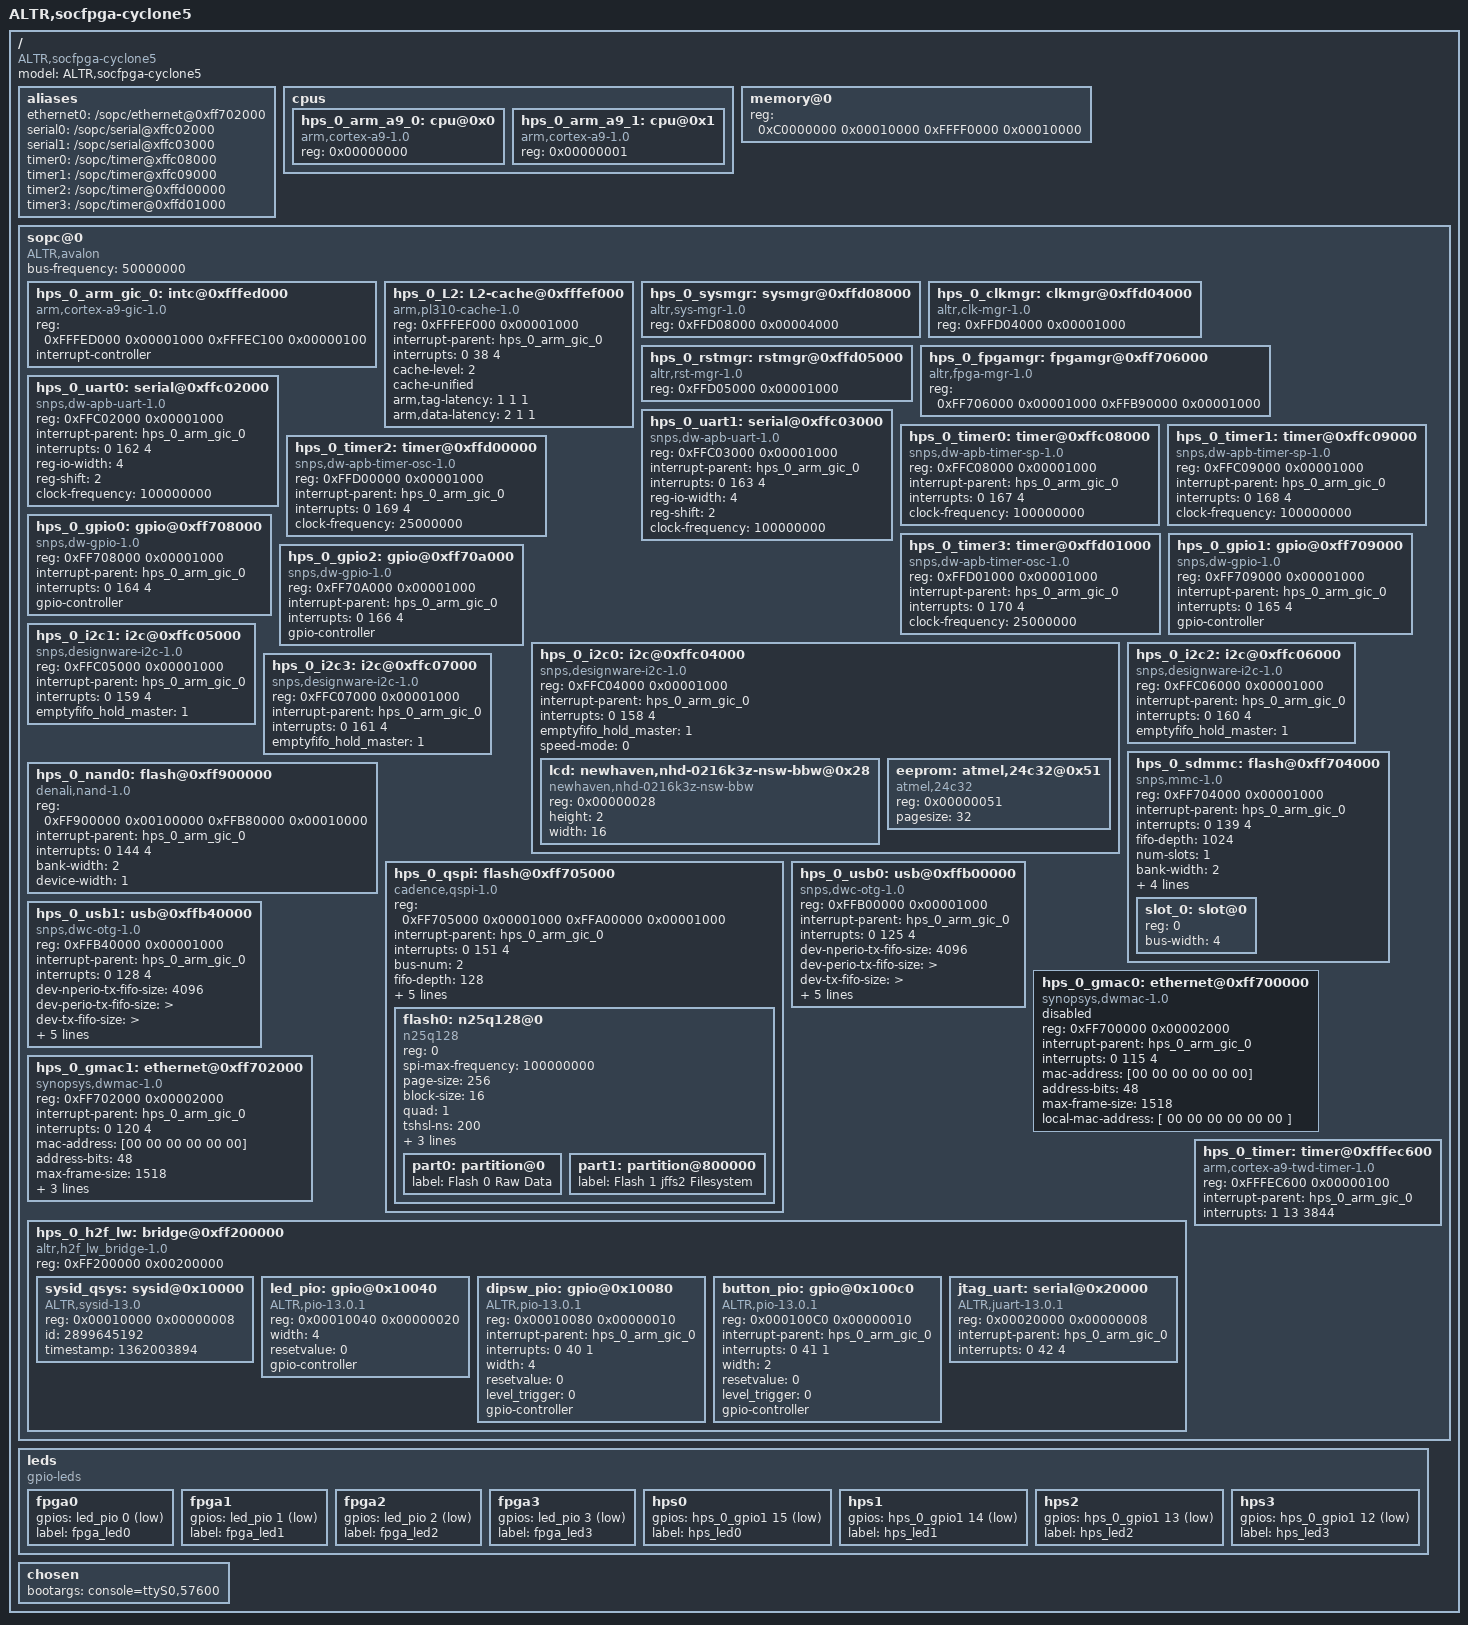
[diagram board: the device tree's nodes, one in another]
/*
 * This devicetree is generated by sopc2dts on Thu Feb 28 06:48:45 MYT 2013
 * Sopc2dts is written by Walter Goossens <waltergoossens@home.nl>
 * in cooperation with the nios2 community <Nios2-dev@sopc.et.ntust.edu.tw>
 */
/dts-v1/;

/ {
	model = "ALTR,socfpga-cyclone5";
	compatible = "ALTR,socfpga-cyclone5";
	#address-cells = < 1 >;
	#size-cells = < 1 >;

	aliases {
		ethernet0 = "/sopc/ethernet@0xff702000";
		serial0 = "/sopc/serial@xffc02000";
		serial1 = "/sopc/serial@xffc03000";
		timer0 = "/sopc/timer@xffc08000";
		timer1 = "/sopc/timer@xffc09000";
		timer2 = "/sopc/timer@0xffd00000";
		timer3 = "/sopc/timer@0xffd01000";
	}; //end aliases

	cpus {
		#address-cells = < 1 >;
		#size-cells = < 0 >;

		hps_0_arm_a9_0: cpu@0x0 {
			device_type = "cpu";
			compatible = "arm,cortex-a9-1.0", "arm,cortex-a9";
			reg = < 0x00000000 >;
		}; //end cpu@0x0 (hps_0_arm_a9_0)

		hps_0_arm_a9_1: cpu@0x1 {
			device_type = "cpu";
			compatible = "arm,cortex-a9-1.0", "arm,cortex-a9";
			reg = < 0x00000001 >;
		}; //end cpu@0x1 (hps_0_arm_a9_1)
	}; //end cpus

	memory@0 {
		device_type = "memory";
		reg = < 0xC0000000 0x00010000
			0xFFFF0000 0x00010000 >;
	}; //end memory@0

	sopc@0 {
		device_type = "soc";
		ranges;
		#address-cells = < 1 >;
		#size-cells = < 1 >;
		compatible = "ALTR,avalon", "simple-bus";
		bus-frequency = < 50000000 >;

		hps_0_arm_gic_0: intc@0xfffed000 {
			compatible = "arm,cortex-a9-gic-1.0", "arm,cortex-a9-gic";
			reg = < 0xFFFED000 0x00001000
				0xFFFEC100 0x00000100 >;
			interrupt-controller;
			#interrupt-cells = < 3 >;
		}; //end intc@0xfffed000 (hps_0_arm_gic_0)

		hps_0_L2: L2-cache@0xfffef000 {
			compatible = "arm,pl310-cache-1.0", "arm,pl310-cache";
			reg = < 0xFFFEF000 0x00001000 >;
			interrupt-parent = < &hps_0_arm_gic_0 >;
			interrupts = < 0 38 4 >;
			cache-level = < 2 >;	/* embeddedsw.dts.params.cache-level type NUMBER */
			cache-unified;	/* appended from boardinfo*/
			arm,tag-latency = <1 1 1>;
			arm,data-latency = <2 1 1>;
		}; //end L2-cache@0xfffef000 (hps_0_L2)

		hps_0_sysmgr: sysmgr@0xffd08000 {
			compatible = "altr,sys-mgr-1.0", "altr,sys-mgr";
			reg = < 0xFFD08000 0x00004000 >;
		}; //end sysmgr@0xffd08000 (hps_0_sysmgr)

		hps_0_clkmgr: clkmgr@0xffd04000 {
			compatible = "altr,clk-mgr-1.0", "altr,clk-mgr";
			reg = < 0xFFD04000 0x00001000 >;
		}; //end clkmgr@0xffd04000 (hps_0_clkmgr)

		hps_0_rstmgr: rstmgr@0xffd05000 {
			compatible = "altr,rst-mgr-1.0", "altr,rst-mgr";
			reg = < 0xFFD05000 0x00001000 >;
		}; //end rstmgr@0xffd05000 (hps_0_rstmgr)

		hps_0_fpgamgr: fpgamgr@0xff706000 {
			compatible = "altr,fpga-mgr-1.0", "altr,fpga-mgr";
			reg = < 0xFF706000 0x00001000
				0xFFB90000 0x00001000 >;
		}; //end fpgamgr@0xff706000 (hps_0_fpgamgr)

		hps_0_uart0: serial@0xffc02000 {
			compatible = "snps,dw-apb-uart-1.0", "snps,dw-apb-uart";
			reg = < 0xFFC02000 0x00001000 >;
			interrupt-parent = < &hps_0_arm_gic_0 >;
			interrupts = < 0 162 4 >;
			reg-io-width = < 4 >;	/* embeddedsw.dts.params.reg-io-width type NUMBER */
			reg-shift = < 2 >;	/* embeddedsw.dts.params.reg-shift type NUMBER */
			clock-frequency = < 100000000 >;	/* appended from boardinfo */
		}; //end serial@0xffc02000 (hps_0_uart0)

		hps_0_uart1: serial@0xffc03000 {
			compatible = "snps,dw-apb-uart-1.0", "snps,dw-apb-uart";
			reg = < 0xFFC03000 0x00001000 >;
			interrupt-parent = < &hps_0_arm_gic_0 >;
			interrupts = < 0 163 4 >;
			reg-io-width = < 4 >;	/* embeddedsw.dts.params.reg-io-width type NUMBER */
			reg-shift = < 2 >;	/* embeddedsw.dts.params.reg-shift type NUMBER */
			clock-frequency = < 100000000 >;	/* appended from boardinfo */
		}; //end serial@0xffc03000 (hps_0_uart1)

		hps_0_timer0: timer@0xffc08000 {
			compatible = "snps,dw-apb-timer-sp-1.0", "snps,dw-apb-timer-sp";
			reg = < 0xFFC08000 0x00001000 >;
			interrupt-parent = < &hps_0_arm_gic_0 >;
			interrupts = < 0 167 4 >;
			clock-frequency = < 100000000 >;	/* appended from boardinfo */
		}; //end timer@0xffc08000 (hps_0_timer0)

		hps_0_timer1: timer@0xffc09000 {
			compatible = "snps,dw-apb-timer-sp-1.0", "snps,dw-apb-timer-sp";
			reg = < 0xFFC09000 0x00001000 >;
			interrupt-parent = < &hps_0_arm_gic_0 >;
			interrupts = < 0 168 4 >;
			clock-frequency = < 100000000 >;	/* appended from boardinfo */
		}; //end timer@0xffc09000 (hps_0_timer1)

		hps_0_timer2: timer@0xffd00000 {
			compatible = "snps,dw-apb-timer-osc-1.0", "snps,dw-apb-timer-osc";
			reg = < 0xFFD00000 0x00001000 >;
			interrupt-parent = < &hps_0_arm_gic_0 >;
			interrupts = < 0 169 4 >;
			clock-frequency = < 25000000 >;	/* appended from boardinfo */
		}; //end timer@0xffd00000 (hps_0_timer2)

		hps_0_timer3: timer@0xffd01000 {
			compatible = "snps,dw-apb-timer-osc-1.0", "snps,dw-apb-timer-osc";
			reg = < 0xFFD01000 0x00001000 >;
			interrupt-parent = < &hps_0_arm_gic_0 >;
			interrupts = < 0 170 4 >;
			clock-frequency = < 25000000 >;	/* appended from boardinfo */
		}; //end timer@0xffd01000 (hps_0_timer3)

		hps_0_gpio0: gpio@0xff708000 {
			compatible = "snps,dw-gpio-1.0", "snps,dw-gpio";
			reg = < 0xFF708000 0x00001000 >;
			interrupt-parent = < &hps_0_arm_gic_0 >;
			interrupts = < 0 164 4 >;
			#gpio-cells = < 2 >;
			gpio-controller;
		}; //end gpio@0xff708000 (hps_0_gpio0)

		hps_0_gpio1: gpio@0xff709000 {
			compatible = "snps,dw-gpio-1.0", "snps,dw-gpio";
			reg = < 0xFF709000 0x00001000 >;
			interrupt-parent = < &hps_0_arm_gic_0 >;
			interrupts = < 0 165 4 >;
			#gpio-cells = < 2 >;
			gpio-controller;
		}; //end gpio@0xff709000 (hps_0_gpio1)

		hps_0_gpio2: gpio@0xff70a000 {
			compatible = "snps,dw-gpio-1.0", "snps,dw-gpio";
			reg = < 0xFF70A000 0x00001000 >;
			interrupt-parent = < &hps_0_arm_gic_0 >;
			interrupts = < 0 166 4 >;
			#gpio-cells = < 2 >;
			gpio-controller;
		}; //end gpio@0xff70a000 (hps_0_gpio2)

		hps_0_i2c0: i2c@0xffc04000 {
			compatible = "snps,designware-i2c-1.0", "snps,designware-i2c";
			reg = < 0xFFC04000 0x00001000 >;
			interrupt-parent = < &hps_0_arm_gic_0 >;
			interrupts = < 0 158 4 >;
			emptyfifo_hold_master = < 1 >;	/* embeddedsw.dts.params.emptyfifo_hold_master type NUMBER */
			#address-cells = < 1 >;
			#size-cells = < 0 >;
			speed-mode = < 0 >;	/* appended from boardinfo */

			lcd: newhaven,nhd-0216k3z-nsw-bbw@0x28 {
				compatible = "newhaven,nhd-0216k3z-nsw-bbw";
				reg = < 0x00000028 >;
				height = < 2 >;	/* appended from boardinfo */
				width = < 16 >;	/* appended from boardinfo */
			}; //end newhaven,nhd-0216k3z-nsw-bbw@0x28 (lcd)

			eeprom: atmel,24c32@0x51 {
				compatible = "atmel,24c32";
				reg = < 0x00000051 >;
				pagesize = < 32 >;	/* appended from boardinfo */
			}; //end atmel,24c32@0x51 (eeprom)
		}; //end i2c@0xffc04000 (hps_0_i2c0)

		hps_0_i2c1: i2c@0xffc05000 {
			compatible = "snps,designware-i2c-1.0", "snps,designware-i2c";
			reg = < 0xFFC05000 0x00001000 >;
			interrupt-parent = < &hps_0_arm_gic_0 >;
			interrupts = < 0 159 4 >;
			emptyfifo_hold_master = < 1 >;	/* embeddedsw.dts.params.emptyfifo_hold_master type NUMBER */
		}; //end i2c@0xffc05000 (hps_0_i2c1)

		hps_0_i2c2: i2c@0xffc06000 {
			compatible = "snps,designware-i2c-1.0", "snps,designware-i2c";
			reg = < 0xFFC06000 0x00001000 >;
			interrupt-parent = < &hps_0_arm_gic_0 >;
			interrupts = < 0 160 4 >;
			emptyfifo_hold_master = < 1 >;	/* embeddedsw.dts.params.emptyfifo_hold_master type NUMBER */
		}; //end i2c@0xffc06000 (hps_0_i2c2)

		hps_0_i2c3: i2c@0xffc07000 {
			compatible = "snps,designware-i2c-1.0", "snps,designware-i2c";
			reg = < 0xFFC07000 0x00001000 >;
			interrupt-parent = < &hps_0_arm_gic_0 >;
			interrupts = < 0 161 4 >;
			emptyfifo_hold_master = < 1 >;	/* embeddedsw.dts.params.emptyfifo_hold_master type NUMBER */
		}; //end i2c@0xffc07000 (hps_0_i2c3)

		hps_0_nand0: flash@0xff900000 {
			compatible = "denali,nand-1.0", "denali,denali-nand-dt";
			reg = < 0xFF900000 0x00100000
				0xFFB80000 0x00010000 >;
			interrupt-parent = < &hps_0_arm_gic_0 >;
			interrupts = < 0 144 4 >;
			#adress-cells = < 1 >;	/* embeddedsw.dts.params.#adress-cells type NUMBER */
			#size-cells = < 1 >;	/* embeddedsw.dts.params.#size-cells type NUMBER */
			reg-names = "nand_data", "denali_reg";	/* embeddedsw.dts.params.reg-names type STRING*/
			bank-width = < 2 >;
			device-width = < 1 >;
		}; //end flash@0xff900000 (hps_0_nand0)

		hps_0_qspi: flash@0xff705000 {
			compatible = "cadence,qspi-1.0", "cadence,qspi";
			reg = < 0xFF705000 0x00001000
				0xFFA00000 0x00001000 >;
			interrupt-parent = < &hps_0_arm_gic_0 >;
			interrupts = < 0 151 4 >;
			bus-num = < 2 >;	/* embeddedsw.dts.params.bus-num type NUMBER */
			fifo-depth = < 128 >;	/* embeddedsw.dts.params.fifo-depth type NUMBER */
			num-chipselect = < 4 >;	/* embeddedsw.dts.params.num-chipselect type NUMBER */
			bank-width = < 2 >;
			device-width = < 1 >;
			master-ref-clk = < 400000000 >;	/* appended from boardinfo */
			ext-decoder = < 0 >;	/* appended from boardinfo */

			flash0: n25q128@0 {
				#address-cells = < 1 >;	/* appended from boardinfo */
				#size-cells = < 1 >;	/* appended from boardinfo */
				compatible = "n25q128";	/* appended from boardinfo*/
				reg = < 0 >;	/* appended from boardinfo */
				spi-max-frequency = < 100000000 >;	/* appended from boardinfo */
				page-size = < 256 >;	/* appended from boardinfo */
				block-size = < 16 >;	/* appended from boardinfo */
				quad = < 1 >;	/* appended from boardinfo */
				tshsl-ns = < 200 >;	/* appended from boardinfo */
				tsd2d-ns = < 255 >;	/* appended from boardinfo */
				tchsh-ns = < 20 >;	/* appended from boardinfo */
				tslch-ns = < 20 >;	/* appended from boardinfo */

				part0: partition@0 {
					label = "Flash 0 Raw Data";	/* appended from boardinfo*/
				}; //end partition@0 (part0)

				part1: partition@800000 {
					label = "Flash 1 jffs2 Filesystem";	/* appended from boardinfo*/
				}; //end partition@800000 (part1)
			}; //end n25q128@0 (flash0)
		}; //end flash@0xff705000 (hps_0_qspi)

		hps_0_sdmmc: flash@0xff704000 {
			compatible = "snps,mmc-1.0", "snps,dw-mshc";
			reg = < 0xFF704000 0x00001000 >;
			interrupt-parent = < &hps_0_arm_gic_0 >;
			interrupts = < 0 139 4 >;
			fifo-depth = < 1024 >;	/* embeddedsw.dts.params.fifo-depth type NUMBER */
			num-slots = < 1 >;	/* embeddedsw.dts.params.num-slots type NUMBER */
			bank-width = < 2 >;
			device-width = < 1 >;
			bus-hz = < 12500000 >;	/* appended from boardinfo */
			#address-cells = < 1 >;	/* appended from boardinfo */
			#size-cells = < 0 >;	/* appended from boardinfo */
			supports-highspeed;	/* appended from boardinfo*/
			broken-cd;	/* appended from boardinfo*/

			slot_0: slot@0 {
				reg = < 0 >;	/* appended from boardinfo */
				bus-width = < 4 >;	/* appended from boardinfo */
			}; //end slot@0 (slot_0)
		}; //end flash@0xff704000 (hps_0_sdmmc)

		hps_0_usb0: usb@0xffb00000 {
			compatible = "snps,dwc-otg-1.0", "snps,dwc-otg";
			reg = < 0xFFB00000 0x00001000 >;
			interrupt-parent = < &hps_0_arm_gic_0 >;
			interrupts = < 0 125 4 >;
			dev-nperio-tx-fifo-size = < 4096 >;	/* embeddedsw.dts.params.dev-nperio-tx-fifo-size type NUMBER */
			dev-perio-tx-fifo-size = ">";	/* embeddedsw.dts.params.dev-perio-tx-fifo-size type STRING*/
			dev-tx-fifo-size = ">";	/* embeddedsw.dts.params.dev-tx-fifo-size type STRING*/
			dev_rx_fifo-size = < 512 >;	/* embeddedsw.dts.params.dev_rx_fifo-size type NUMBER */
			dma-mask = < 268435455 >;	/* embeddedsw.dts.params.dma-mask type NUMBER */
			host_rx_fifo-size = < 512 >;	/* embeddedsw.dts.params.host_rx_fifo-size type NUMBER */
			ulpi-ddr = < 0 >;	/* embeddedsw.dts.params.ulpi-ddr type NUMBER */
			voltage-switch = < 0 >;	/* embeddedsw.dts.params.voltage-switch type NUMBER */
		}; //end usb@0xffb00000 (hps_0_usb0)

		hps_0_usb1: usb@0xffb40000 {
			compatible = "snps,dwc-otg-1.0", "snps,dwc-otg";
			reg = < 0xFFB40000 0x00001000 >;
			interrupt-parent = < &hps_0_arm_gic_0 >;
			interrupts = < 0 128 4 >;
			dev-nperio-tx-fifo-size = < 4096 >;	/* embeddedsw.dts.params.dev-nperio-tx-fifo-size type NUMBER */
			dev-perio-tx-fifo-size = ">";	/* embeddedsw.dts.params.dev-perio-tx-fifo-size type STRING*/
			dev-tx-fifo-size = ">";	/* embeddedsw.dts.params.dev-tx-fifo-size type STRING*/
			dev_rx_fifo-size = < 512 >;	/* embeddedsw.dts.params.dev_rx_fifo-size type NUMBER */
			dma-mask = < 268435455 >;	/* embeddedsw.dts.params.dma-mask type NUMBER */
			host_rx_fifo-size = < 512 >;	/* embeddedsw.dts.params.host_rx_fifo-size type NUMBER */
			ulpi-ddr = < 0 >;	/* embeddedsw.dts.params.ulpi-ddr type NUMBER */
			voltage-switch = < 0 >;	/* embeddedsw.dts.params.voltage-switch type NUMBER */
		}; //end usb@0xffb40000 (hps_0_usb1)

		hps_0_gmac0: ethernet@0xff700000 {
			compatible = "synopsys,dwmac-1.0", "altr,socfpga-stmmac", "snps,dwmac-3.70a", "snps,dwmac";
			reg = < 0xFF700000 0x00002000 >;
			interrupt-parent = < &hps_0_arm_gic_0 >;
			interrupts = < 0 115 4 >;
			interrupt-names = "macirq";	/* embeddedsw.dts.params.interrupt-names type STRING*/
			mac-address = "[00 00 00 00 00 00]";	/* embeddedsw.dts.params.mac-address type STRING*/
			address-bits = < 48 >;
			max-frame-size = < 1518 >;
			local-mac-address = [ 00 00 00 00 00 00 ];
			status = "disabled";	/* appended from boardinfo*/
		}; //end ethernet@0xff700000 (hps_0_gmac0)

		hps_0_gmac1: ethernet@0xff702000 {
			compatible = "synopsys,dwmac-1.0", "altr,socfpga-stmmac", "snps,dwmac-3.70a", "snps,dwmac";
			reg = < 0xFF702000 0x00002000 >;
			interrupt-parent = < &hps_0_arm_gic_0 >;
			interrupts = < 0 120 4 >;
			interrupt-names = "macirq";	/* embeddedsw.dts.params.interrupt-names type STRING*/
			mac-address = "[00 00 00 00 00 00]";	/* embeddedsw.dts.params.mac-address type STRING*/
			address-bits = < 48 >;
			max-frame-size = < 1518 >;
			local-mac-address = [ 00 00 00 00 00 00 ];
			phy-mode = "rgmii";	/* appended from boardinfo*/
			phy-addr = < 0xffffffff >;	/* appended from boardinfo */
		}; //end ethernet@0xff702000 (hps_0_gmac1)

		hps_0_h2f_lw: bridge@0xff200000 {
			compatible = "altr,h2f_lw_bridge-1.0", "simple-bus";
			reg = < 0xFF200000 0x00200000 >;
			#address-cells = < 1 >;
			#size-cells = < 1 >;
			ranges = < 0x00010000 0xFF210000 0x00000008
				0x00010040 0xFF210040 0x00000020
				0x00010080 0xFF210080 0x00000010
				0x000100C0 0xFF2100C0 0x00000010
				0x00020000 0xFF220000 0x00000008 >;

			sysid_qsys: sysid@0x10000 {
				compatible = "ALTR,sysid-13.0", "ALTR,sysid-1.0";
				reg = < 0x00010000 0x00000008 >;
				id = < 2899645192 >;	/* embeddedsw.dts.params.id type NUMBER */
				timestamp = < 1362003894 >;	/* embeddedsw.dts.params.timestamp type NUMBER */
			}; //end sysid@0x10000 (sysid_qsys)

			led_pio: gpio@0x10040 {
				compatible = "ALTR,pio-13.0.1", "ALTR,pio-1.0", "altr,pio-1.0";
				reg = < 0x00010040 0x00000020 >;
				width = < 4 >;	/* width type NUMBER */
				resetvalue = < 0 >;	/* resetValue type NUMBER */
				#gpio-cells = < 2 >;
				gpio-controller;
			}; //end gpio@0x10040 (led_pio)

			dipsw_pio: gpio@0x10080 {
				compatible = "ALTR,pio-13.0.1", "ALTR,pio-1.0", "altr,pio-1.0";
				reg = < 0x00010080 0x00000010 >;
				interrupt-parent = < &hps_0_arm_gic_0 >;
				interrupts = < 0 40 1 >;
				width = < 4 >;	/* width type NUMBER */
				resetvalue = < 0 >;	/* resetValue type NUMBER */
				level_trigger = < 0 >;	/* embeddedsw.dts.params.level_trigger type NUMBER */
				#gpio-cells = < 2 >;
				gpio-controller;
			}; //end gpio@0x10080 (dipsw_pio)

			button_pio: gpio@0x100c0 {
				compatible = "ALTR,pio-13.0.1", "ALTR,pio-1.0", "altr,pio-1.0";
				reg = < 0x000100C0 0x00000010 >;
				interrupt-parent = < &hps_0_arm_gic_0 >;
				interrupts = < 0 41 1 >;
				width = < 2 >;	/* width type NUMBER */
				resetvalue = < 0 >;	/* resetValue type NUMBER */
				level_trigger = < 0 >;	/* embeddedsw.dts.params.level_trigger type NUMBER */
				#gpio-cells = < 2 >;
				gpio-controller;
			}; //end gpio@0x100c0 (button_pio)

			jtag_uart: serial@0x20000 {
				compatible = "ALTR,juart-13.0.1", "ALTR,juart-1.0";
				reg = < 0x00020000 0x00000008 >;
				interrupt-parent = < &hps_0_arm_gic_0 >;
				interrupts = < 0 42 4 >;
			}; //end serial@0x20000 (jtag_uart)
		}; //end bridge@0xff200000 (hps_0_h2f_lw)

		hps_0_timer: timer@0xfffec600 {
			compatible = "arm,cortex-a9-twd-timer-1.0", "arm,cortex-a9-twd-timer";
			reg = < 0xFFFEC600 0x00000100 >;
			interrupt-parent = < &hps_0_arm_gic_0 >;
			interrupts = < 1 13 3844 >;
		}; //end timer@0xfffec600 (hps_0_timer)
	}; //end sopc@0

	leds {
		compatible = "gpio-leds";
		fpga0 {
			gpios = <&led_pio 0 1>;
			label = "fpga_led0";
		};
		fpga1 {
			gpios = <&led_pio 1 1>;
			label = "fpga_led1";
		};
		fpga2 {
			gpios = <&led_pio 2 1>;
			label = "fpga_led2";
		};
		fpga3 {
			gpios = <&led_pio 3 1>;
			label = "fpga_led3";
		};
		hps0 {
			gpios = <&hps_0_gpio1 15 1>;
			label = "hps_led0";
		};
		hps1 {
			gpios = <&hps_0_gpio1 14 1>;
			label = "hps_led1";
		};
		hps2 {
			gpios = <&hps_0_gpio1 13 1>;
			label = "hps_led2";
		};
		hps3 {
			gpios = <&hps_0_gpio1 12 1>;
			label = "hps_led3";
		};
	};
	chosen {
		bootargs = "console=ttyS0,57600";
	}; //end chosen
}; //end /
